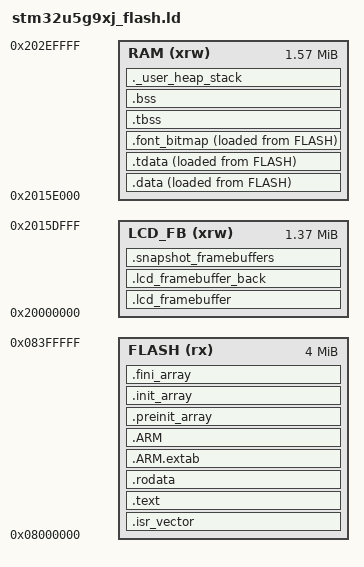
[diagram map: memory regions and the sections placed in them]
/*
******************************************************************************
**
** @brief       : Linker script for STM32U5G9xJ devices from STM32U5 series
**                      4096KBytes FLASH
**                      3008KBytes RAM
**
**                Set heap size, stack size and stack location according
**                to application requirements.
**
**                Set memory bank area and size if external memory is used
**
**  Target      : STMicroelectronics STM32
**
**  Distribution: The file is distributed as is, without any warranty
**                of any kind.
**
******************************************************************************
** @attention
**
** Copyright (c) 2026 STMicroelectronics.
** All rights reserved.
**
** This software is licensed under terms that can be found in the LICENSE file
** in the root directory of this software component.
** If no LICENSE file comes with this software, it is provided AS-IS.
**
******************************************************************************
*/

/* Memories definition */
MEMORY
{
  /* Two 390x450 RGB565 scanout buffers plus two fixed full-screen snapshots.
   * The region is rounded up to a 4 KiB boundary. */
  LCD_FB (xrw)    : ORIGIN = 0x20000000,   LENGTH = 1400K
  RAM    (xrw)    : ORIGIN = 0x2015E000,   LENGTH = 1608K
  FLASH    (rx)    : ORIGIN = 0x8000000,   LENGTH = 4096K
}

/* Entry Point */
ENTRY(Reset_Handler)

/* Highest address of the user mode stack */
_estack = ORIGIN(RAM) + LENGTH(RAM); /* end of "RAM" Ram type memory */
_sstack = _estack - _Min_Stack_Size;

_Min_Heap_Size = 0x200; /* required amount of heap */
/* ElenixOS creates the initial UI tree and script runtime synchronously. */
_Min_Stack_Size = 0x10000; /* 64 KiB stack */

/* Sections */
SECTIONS
{

  /* Keep the centered logical LTDC framebuffer reserved. */
  .lcd_framebuffer (NOLOAD) :
  {
    . = ALIGN(32);
    . = . + 390 * 450 * 2;
    . = ALIGN(32);
  } >LCD_FB

  /* The application framebuffer_b[] is the second page-flipped scanout
   * buffer.  Keep it after the fixed first framebuffer. */
  .lcd_framebuffer_back (NOLOAD) :
  {
    . = ALIGN(32);
    KEEP(*(.lcd_framebuffer_back))
    . = ALIGN(32);
  } >LCD_FB

  /* U5 animation snapshots are fixed-size and never consume a fragmented
   * runtime heap. */
  .snapshot_framebuffers (NOLOAD) :
  {
    . = ALIGN(32);
    KEEP(*(.snapshot_framebuffers))
    . = ALIGN(32);
  } >LCD_FB

  /* The startup code into "FLASH" Rom type memory */
  .isr_vector :
  {
    . = ALIGN(4);
    KEEP(*(.isr_vector)) /* Startup code */
    . = ALIGN(4);
  } >FLASH

  /* The program code and other data into "FLASH" Rom type memory */
  .text :
  {
    . = ALIGN(4);
    *(.text)           /* .text sections (code) */
    *(.text*)          /* .text* sections (code) */
    *(.glue_7)         /* glue arm to thumb code */
    *(.glue_7t)        /* glue thumb to arm code */
    *(.eh_frame)
    KEEP (*(.init))
    KEEP (*(.fini))
    . = ALIGN(4);
    _etext = .;        /* define a global symbols at end of code */
  } >FLASH

  /* Constant data into "FLASH" Rom type memory */
  .rodata :
  {
    . = ALIGN(4);
    *(.rodata)         /* .rodata sections (constants, strings, etc.) */
    *(.rodata*)        /* .rodata* sections (constants, strings, etc.) */
    . = ALIGN(4);
  } >FLASH

  .ARM.extab (READONLY) : /* The "READONLY" keyword is only supported in GCC11 and later, remove it if using GCC10 or earlier. */
  {
    . = ALIGN(4);
    *(.ARM.extab* .gnu.linkonce.armextab.*)
    . = ALIGN(4);
  } >FLASH

  .ARM (READONLY) : /* The "READONLY" keyword is only supported in GCC11 and later, remove it if using GCC10 or earlier. */
  {
    . = ALIGN(4);
    __exidx_start = .;
    *(.ARM.exidx*)
    __exidx_end = .;
    . = ALIGN(4);
  } >FLASH

  .preinit_array (READONLY) : /* The "READONLY" keyword is only supported in GCC11 and later, remove it if using GCC10 or earlier. */
  {
    . = ALIGN(4);
    PROVIDE_HIDDEN (__preinit_array_start = .);
    KEEP (*(.preinit_array*))
    PROVIDE_HIDDEN (__preinit_array_end = .);
    . = ALIGN(4);
  } >FLASH

  .init_array (READONLY) : /* The "READONLY" keyword is only supported in GCC11 and later, remove it if using GCC10 or earlier. */
  {
    . = ALIGN(4);
    PROVIDE_HIDDEN (__init_array_start = .);
    KEEP (*(SORT(.init_array.*)))
    KEEP (*(.init_array*))
    PROVIDE_HIDDEN (__init_array_end = .);
    . = ALIGN(4);
  } >FLASH

  .fini_array (READONLY) : /* The "READONLY" keyword is only supported in GCC11 and later, remove it if using GCC10 or earlier. */
  {
    . = ALIGN(4);
    PROVIDE_HIDDEN (__fini_array_start = .);
    KEEP (*(SORT(.fini_array.*)))
    KEEP (*(.fini_array*))
    PROVIDE_HIDDEN (__fini_array_end = .);
    . = ALIGN(4);
  } >FLASH

  /* Used by the startup to initialize data */
  _sidata = LOADADDR(.data);

  /* Initialized data section */
  .data : ALIGN(4)
  {
    _sdata = .;        /* create a global symbol at data start */
    *(.data)           /* .data sections */
    *(.data*)          /* .data* sections */
    *(.RamFunc)        /* .RamFunc sections */
    *(.RamFunc*)       /* .RamFunc* sections */
    . = ALIGN(4);
  } >RAM AT> FLASH

  .tdata : ALIGN(4)
  {
    *(.tdata .tdata.* .gnu.linkonce.td.*)
    . = ALIGN(4);
    _edata = .;        /* define a global symbol at data end */
    PROVIDE(__data_end = .);
    PROVIDE(__tdata_end = .);
  } >RAM AT> FLASH
  PROVIDE( __tdata_start = ADDR(.tdata) );
  PROVIDE( __tdata_size = __tdata_end - __tdata_start );

  PROVIDE( __data_start = ADDR(.data) );
  PROVIDE( __data_size = __data_end - __data_start );

  /* Font glyphs are linked into SRAM for direct GPU2D raw-glyph reads. */
  .font_bitmap : ALIGN(32)
  {
    __font_bitmap_start__ = .;
    KEEP(*(.font_bitmap))
    KEEP(*(.font_bitmap.*))
    . = ALIGN(32);
    __font_bitmap_end__ = .;
  } >RAM AT> FLASH
  __font_bitmap_load__ = LOADADDR(.font_bitmap);

  PROVIDE( __tdata_source = LOADADDR(.tdata) );
  PROVIDE( __tdata_source_end = LOADADDR(.tdata) + SIZEOF(.tdata) );
  PROVIDE( __tdata_source_size = __tdata_source_end - __tdata_source );

  PROVIDE( __data_source = LOADADDR(.data) );
  PROVIDE( __data_source_end = __tdata_source_end );
  PROVIDE( __data_source_size = __data_source_end - __data_source );

  /* Uninitialized data section */
  .tbss (NOLOAD) : ALIGN(4)
  {
    /* This is used by the startup in order to initialize the .bss and .tbss sections */
    _sbss = .;         /* define a global symbol at bss start */
    __bss_start__ = _sbss;
    PROVIDE( __bss_start = . );
    *(.tbss .tbss.*)
    . = ALIGN(4);
    PROVIDE( __tbss_end = . );
  } >RAM
  PROVIDE( __tbss_start = ADDR(.tbss) );
  PROVIDE( __tbss_size = __tbss_end - __tbss_start );
  PROVIDE( __tbss_offset = ADDR(.tbss) - ADDR(.tdata) );

  PROVIDE( __tls_base = __tdata_start );
  PROVIDE( __tls_end = __tbss_end );
  PROVIDE( __tls_size = __tls_end - __tls_base );
  PROVIDE( __tls_align = MAX(ALIGNOF(.tdata), ALIGNOF(.tbss)) );
  PROVIDE( __tls_size_align = (__tls_size + __tls_align - 1) & ~(__tls_align - 1) );
  PROVIDE( __arm32_tls_tcb_offset = MAX(8, __tls_align) );
  PROVIDE( __arm64_tls_tcb_offset = MAX(16, __tls_align) );

  .bss (NOLOAD) : ALIGN(4)
  {
    *(.bss)
    *(.bss*)
    *(COMMON)
    . = ALIGN(4);
    _ebss = .;         /* define a global symbol at bss end */
    __bss_end__ = _ebss;
    PROVIDE( __bss_end = . );
  } >RAM
  PROVIDE( __bss_size = __bss_end - __bss_start );
  PROVIDE( __non_tls_bss_start = ADDR(.bss) );

  /* User_heap_stack section, used to check that there is enough "RAM" Ram  type memory left */
  ._user_heap_stack (NOLOAD) :
  {
    . = ALIGN(8);
    PROVIDE ( end = . );
    PROVIDE ( _end = . );
    . = . + _Min_Heap_Size;
    . = . + _Min_Stack_Size;
    . = ALIGN(8);
  } >RAM

  /* Remove information from the compiler libraries */
  /DISCARD/ :
  {
    libc.a:* ( * )
    libm.a:* ( * )
    libgcc.a:* ( * )
  }

  .ARM.attributes 0 : { *(.ARM.attributes) }
}
